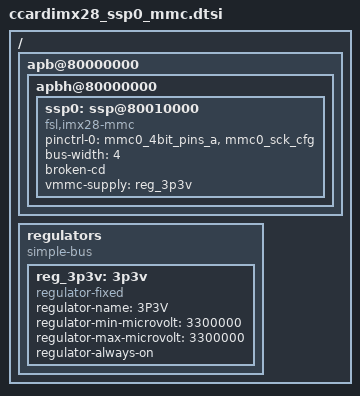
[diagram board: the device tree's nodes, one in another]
/*
 * Copyright 2013 Digi International, Inc.
 *
 * The code contained herein is licensed under the GNU General Public
 * License. You may obtain a copy of the GNU General Public License
 * Version 2 or later at the following locations:
 *
 * http://www.opensource.org/licenses/gpl-license.html
 * http://www.gnu.org/copyleft/gpl.html
 */

/ {
	apb@80000000 {
		apbh@80000000 {
			ssp0: ssp@80010000 {
				compatible = "fsl,imx28-mmc";
				pinctrl-names = "default";
				pinctrl-0 = <&mmc0_4bit_pins_a &mmc0_sck_cfg>;
				bus-width = <4>;
				broken-cd;
				vmmc-supply = <&reg_3p3v>;
				status = "okay";
			};
		};
	};

	regulators {
		compatible = "simple-bus";

		reg_3p3v: 3p3v {
			compatible = "regulator-fixed";
			regulator-name = "3P3V";
			regulator-min-microvolt = <3300000>;
			regulator-max-microvolt = <3300000>;
			regulator-always-on;
		};
	};
};
